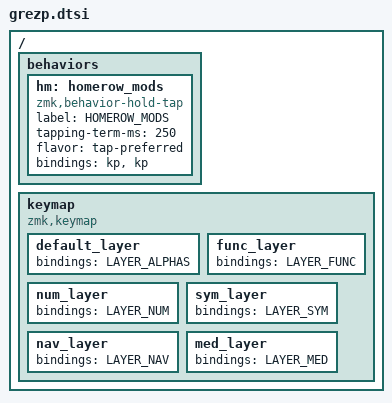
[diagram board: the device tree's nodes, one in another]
/*
 * Copyright (c) 2020 The ZMK Contributors
 *
 * SPDX-License-Identifier: MIT
 */

#include <behaviors.dtsi>
#include <dt-bindings/zmk/keys.h>
#include <dt-bindings/zmk/bt.h>

#include "keymap_definitions.h"

/ {
    behaviors {
        hm: homerow_mods {
            compatible = "zmk,behavior-hold-tap";
            label = "HOMEROW_MODS";
            #binding-cells = <2>;
            tapping-term-ms = <250>;
            flavor = "tap-preferred";
            bindings = <&kp>, <&kp>;
        };
    };
};

/ {
    keymap {
        compatible = "zmk,keymap";

        default_layer {
            bindings = <LAYER_ALPHAS>;
        };

        func_layer {
            bindings = <LAYER_FUNC>;
        };

        num_layer {
            bindings = <LAYER_NUM>;
        };

        sym_layer {
            bindings = <LAYER_SYM>;
        };

        nav_layer {
            bindings = <LAYER_NAV>;
        };

        med_layer {
            bindings = <LAYER_MED>;
        };
    };
};
